# CFGS2 register map
Registers from a debugger description file.
Registers are 32-bit, access not given, no defined reset value unless marked. A register's access mark holds for its fields unless they carry their own. Addresses are absolute; registers are grouped by the start of their names; lines under a group give offsets from that group; [hi:lo] are bit positions; {n}, {i} and the like mark numbered series; 'fields as' and 'values as' point back to an identical list; <NAME> marks a mode.

## Level2
{0x51000000+4i} Level2_Config_{i} (i=0..169)
  [5:0] IOFunction
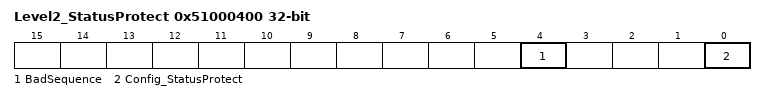
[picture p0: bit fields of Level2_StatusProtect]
0x51000400 Level2_StatusProtect
  [4] BadSequence, [0] Config_StatusProtect
0x51000404 Level2_Config_MDIO1
  [2:0] Config_MDIO1
0x51000408 Level2_Config_MDIO2
  [2:0] Config_MDIO2
{0x51000480+4i} Level2_GPIO_Int_{i} (i=0..7)
  [6:0] GPIO_Int
